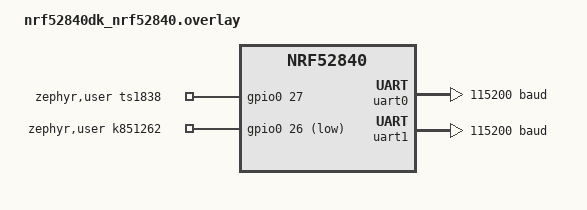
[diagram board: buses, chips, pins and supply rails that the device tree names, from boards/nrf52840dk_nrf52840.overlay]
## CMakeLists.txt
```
# SPDX-License-Identifier: Apache-2.0

cmake_minimum_required(VERSION 3.20.0)
find_package(Zephyr REQUIRED HINTS $ENV{ZEPHYR_BASE})
project(transmitter)

list(APPEND CMAKE_MODULE_PATH ${ZEPHYR_BASE}/modules/nanopb)
include(nanopb)
zephyr_nanopb_sources(app src/pc.proto)
FILE(GLOB app_sources src/*.c)

target_sources(app PRIVATE ${app_sources})

# ORIGINAL Targets (No NanoPB)
# target_sources(app PRIVATE src/main.c)
# zephyr_sources(src/shell_commands.c)
# zephyr_sources(src/hci.c)
# zephyr_sources(src/led_module.c)
# zephyr_sources(src/uart_module.c)
# zephyr_sources(src/ahu.c)
# zephyr_sources(src/ble_module.c)
# zephyr_sources(src/gcu_shell_cmds.c)
# zephyr_sources(src/ab_util.c)
```

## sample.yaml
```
sample:
  name: AHU
common:
  modules:
    - nanopb
tests:
  sample.basic.blinky:
    tags:
      - LED
      - gpio
    filter: dt_enabled_alias_with_parent_compat("led0", "gpio-leds")
    depends_on: gpio
    harness: led
    integration_platforms:
      - frdm_k64f
```

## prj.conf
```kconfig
# Configure GPIO (for LEDS)
CONFIG_GPIO=y

# Configure Logging & Shell
CONFIG_PRINTK=y
CONFIG_SHELL=y
CONFIG_SHELL_LOG_BACKEND=y
CONFIG_LOG=y
CONFIG_LOG_CMDS=y
CONFIG_LOG_RUNTIME_FILTERING=y
CONFIG_LOG_SPEED=y
CONFIG_LOG_DEFAULT_LEVEL=3
CONFIG_LOG_PRINTK=y
CONFIG_STATS=y
CONFIG_STATS_SHELL=y
CONFIG_CBPRINTF_FP_SUPPORT=y

# Uart
CONFIG_SERIAL=y
CONFIG_UART_INTERRUPT_DRIVEN=y

# RTT
CONFIG_USE_SEGGER_RTT=y
CONFIG_UART_CONSOLE=n
CONFIG_RTT_CONSOLE=y
CONFIG_SHELL_BACKEND_RTT=y
CONFIG_LOG_BACKEND_RTT_BUFFER=1
CONFIG_SHELL_BACKEND_RTT_BUFFER=0

# Bluetooth
CONFIG_BT=y
CONFIG_BT_OBSERVER=y
CONFIG_BT_SHELL=y
CONFIG_BT_FILTER_ACCEPT_LIST=y

# CONFIG
# CONFIG_INIT_STACKS=y
# CONFIG_THREAD_STACK_INFO=y
# CONFIG_KERNEL_SHELL=y
# CONFIG_THREAD_MONITOR=y
# CONFIG_BOOT_BANNER=n
# CONFIG_THREAD_NAME=y
# CONFIG_DEVICE_SHELL=y
# CONFIG_POSIX_CLOCK=y
# CONFIG_DATE_SHELL=y
# CONFIG_THREAD_RUNTIME_STATS=y
# CONFIG_THREAD_RUNTIME_STATS_USE_TIMING_FUNCTIONS=y
CONFIG_HEAP_MEM_POOL_SIZE=8192
CONFIG_NANOPB=y
# CONFIG_BT_CTLR_RX_PRIO_STACK_SIZE=2048
# CONFIG_MAIN_STACK_SIZE=16384
```

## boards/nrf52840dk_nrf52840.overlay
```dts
/*
 * Copyright (c) 2021 Jonathan Hahn
 *
 * SPDX-License-Identifier: Apache-2.0
 */

 / 
{
	zephyr,user {
		ts1838-gpios = <&gpio0 27 GPIO_ACTIVE_HIGH>;
		k851262-gpios = <&gpio0 26 GPIO_ACTIVE_LOW>;
	};
    
	aliases {
      uart-test = &uart1;
	  pc-software = &uart0;
	  ir-rx = &gpio0;
	  ir-tx = &gpio0;
	  ir-gpio = &gpio0;
   };
};

&uart0 {
	compatible = "nordic,nrf-uarte";
	status = "okay";
	current-speed = <115200>;
	pinctrl-0 = <&uart0_default>;
	pinctrl-1 = <&uart0_sleep>;
	pinctrl-names = "default", "sleep";
};

&uart1 {
	status = "okay";
	current-speed = <115200>;
	pinctrl-0 = <&uart1_default>;
	pinctrl-1 = <&uart1_sleep>;
	pinctrl-names = "default", "sleep";
};

&gpio0 {
	status = "okay";
	gpio-reserved-ranges = <0 2>, <6 1>, <8 3>, <17 7>;
	gpio-line-names = "XL1", "XL2", "AREF", "A0", "A1", "RTS", "TXD",
		"CTS", "RXD", "NFC1", "NFC2", "BUTTON1", "BUTTON2", "LED1",
		"LED2", "LED3", "LED4", "QSPI CS", "RESET", "QSPI CLK",
		"QSPI DIO0", "QSPI DIO1", "QSPI DIO2", "QSPI DIO3","BUTTON3",
		"BUTTON4", "SDA", "SCL", "A2", "A3", "A4", "A5";
};
```

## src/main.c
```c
 /** 
 **************************************************************
 * @file src/main.c
 * @author Alexander Burovanov - 46990480
 * @date 01052023
 * @brief Application Host Unit (AHU) Entry Point
 * REFERENCE: csse4011_prac1_ahu.pdf 
 ***************************************************************
 */

#include <stdio.h>
#include <zephyr/kernel.h>
#include <zephyr/sys_clock.h>
#include <zephyr/device.h>
#include <zephyr/sys/sys_heap.h>
#include "ahu.h"
#include "led_module.h"
#include "uart_module.h"
#include "ble_module.h"
#include "pc_module.h"
#include "ir_module.h"

// Define Priorities
#define UART_PRIORITY 2
#define AHU_PRIORITY 3
#define BLE_PRIORITY 3
#define PC_PRIORITY 3
#define IR_TX_PRIORITY 1

// Define Stack Sizes
#define UART_STACK_SIZE 1024
#define AHU_STACK_SIZE 2048
#define BLE_STACK_SIZE 4096
#define PC_STACK_SIZE 8192
#define IR_TX_STACK_SIZE 2048

// Create threads
K_THREAD_DEFINE(ahu_id, AHU_STACK_SIZE, ahu_handler, NULL, NULL, NULL,
		AHU_PRIORITY, 0, 0);
K_THREAD_DEFINE(uart_id, UART_STACK_SIZE, uart_handler, NULL, NULL, NULL,
		UART_PRIORITY, 0, 0);
K_THREAD_DEFINE(ble_id, BLE_STACK_SIZE, ble_handler, NULL, NULL, NULL,
		BLE_PRIORITY, 0, 0);
K_THREAD_DEFINE(pc_transmit_id, PC_STACK_SIZE, pc_comms_transmit_handler, NULL, NULL, NULL,
		PC_PRIORITY, 0, 0);
K_THREAD_DEFINE(pc_receive_id, PC_STACK_SIZE, pc_comms_receive_handler, NULL, NULL, NULL,
		PC_PRIORITY, 0, 0);		
K_THREAD_DEFINE(ir_tx_id, IR_TX_STACK_SIZE, ir_transmission_handler, NULL, NULL, NULL,
		IR_TX_PRIORITY, 0, 0);

/**
 * Application entry point
 * 
 * Returns: 0 upon exit
*/
int main(void) {

	// Initialise Hardware
	init_leds();
	init_ble();
	init_ir_module();

	return 0;
}
```

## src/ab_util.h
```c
 /** 
 **************************************************************
 * @file src/ab_util.h
 * @author Alexander Burovanov - 46990480
 * @date 25/03/2024
 * @brief AB's Utility Library
 * REFERENCE: None
 ***************************************************************
 */
#ifndef AB_UTIL_H_
#define AB_UTIL_H_
#include <zephyr/shell/shell.h>
#include <version.h>
#include <zephyr/logging/log.h>
#include <stdio.h>
#include <stdlib.h>
#include <zephyr/bluetooth/addr.h>
#include "uart_module.h"
#include "hci.h"
#include "led_module.h"
// #include "ble_module.h"

/**
 * Validates a floating point argument
 * 
 * value: the value to validate
 * returnLoc: a pointer to the return location
 * 
 * Returns: 0 on success, otherwise 1.
*/
extern int validate_float_arg(char* value, float* returnLoc);

/**
 * Validates an integer argument
 * 
 * value: the value to validate
 * returnLoc: a pointer to the return location
 * 
 * Returns: 0 on success, otherwise 1.
*/
extern int validate_int_arg(char* value, int* returnLoc);

/**
 * Validates a provided binary command line argument
 * 
 * value: the character to validate
 * 
 * Returns: 0 if value is 0, 1 if value is 1, 2 on error.
*/
extern int validate_binary_arg(char value);

/**
 * Gets a binary mask from a mask string
 * 
 * mask: a ptr to store the resulting mask
 * value: a string mask. E.g. "0010"
 * length: the length of the target mask E.g. 4
 * 
 * Returns: 0 on success, otherwise 1.
*/
extern uint8_t get_binary_mask(uint8_t* mask, char *value, uint8_t length);

/**
 * Validates a device id argument.
 * 
 * did: device id to verify
 * 
 * Result: 0 if valid, 1 otherwise.
*/
extern int validate_device_id(uint8_t did);

/**
 * Validates a provided filename arguments
 * 
 * fileName: filename being validated
 * 
 * Returns: 0 if valid. 1 if the filename is too long. 2 if the filename is invalid. 3 if the extension is invalid.
 * 
*/
extern int validate_file_name(char* fileName);

/**
 * Validates an BLE Address argument
 * 
 * value: the value to validate
 * returnLoc: a pointer to the return location
 * 
 * Returns: 0 on success, otherwise 1.
*/
extern int validate_ble_addr(char* value, bt_addr_le_t* returnLoc);

#endif
```

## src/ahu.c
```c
 /** 
 **************************************************************
 * @file src/ahu.c
 * @author Alexander Burovanov - 46990480
 * @date 01052023
 * @brief Application Host Unit Module
 * REFERENCE: csse4011_prac1_ahu.pdf 
 ***************************************************************
 */
#include <zephyr/kernel.h>
#include <zephyr/shell/shell.h>
#include <zephyr/logging/log.h>
#include <zephyr/logging/log_ctrl.h>
#include <zephyr/drivers/uart.h>

#include "ahu.h"
#include "hci.h"
#include "uart_module.h"
#include "pc_module.h"
#include "src/pc.pb.h"

// Register Logger
LOG_MODULE_REGISTER(ahu);

/* 1000 msec = 1 sec */
#define SLEEP_TIME_MS   1000

/**
 * Initialises the runtime logging levels for the project
 * 
 * Returns: 0 on exit
*/
static int initalise_log_levels(const struct device *dev) {
    ARG_UNUSED(dev);

	LogModule log_modules[] = {
		{"hci", LOG_LEVEL_INF},
        {"led_module", LOG_LEVEL_INF}
	};

	for (uint8_t i = 0; i < ARRAY_SIZE(log_modules); i++) {
		int sourceId = log_source_id_get(log_modules[i].module);
        if (sourceId < 0) {
            printk("Error: Log module %s not found\n", log_modules[i].module);
            continue;
        }
		log_filter_set(NULL, 0, sourceId, log_modules[i].level);
	}
    return 0;
}

SYS_INIT(initalise_log_levels, APPLICATION, CONFIG_APPLICATION_INIT_PRIORITY);

/**
 * AHU handler - handles the shell and interacts with the UART
 * 
 * Returns: 0 upon exit
*/
int ahu_handler(void) {
    const struct device *dev;
	uint32_t dtr = 0;

	dev = DEVICE_DT_GET(DT_CHOSEN(zephyr_shell_uart));
	if (!device_is_ready(dev)) {
		return 0;
	}

	while (!dtr) {
		#ifdef UART_SHELL
		uart_line_ctrl_get(dev, UART_LINE_CTRL_DTR, &dtr);
		k_sleep(K_MSEC(100));
		#endif

		#ifndef UART_SHELL
		// Run AHU in IR mode
		LOG_INF("Powered On");
		return 0;
		#endif
	}

    return 0;
}
```

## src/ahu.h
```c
 /** 
 **************************************************************
 * @file src/ahu.h
 * @author Alexander Burovanov - 46990480
 * @date 01052023
 * @brief Application Host Unit Module
 * REFERENCE: csse4011_prac1_ahu.pdf 
 ***************************************************************
 */
#ifndef AHU_H_
#define AHU_H_

// Groups a log module with an associated severity
typedef struct {
    const char* module;
    uint32_t level;
} LogModule;

// UART SHELL CONTROL
// Activate UART shell logic, otherwise default to using UART for GUI connection
// #define UART_SHELL

// THINGY52 BT CONTROL
// The AHU has the capability to automatically connect to a THINGY:52 and stream data from it's sensors to a PC.
// Uncomment the line below to activate this functionality
// #define THINGY52_BT

/**
 * AHU handler which handles the shell
 * 
 * Returns: 0 upon exit
*/
extern int ahu_handler(void);

#endif
```

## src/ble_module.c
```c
 /** 
 **************************************************************
 * @file src/ble_module.c
 * @author Alexander Burovanov - 46990480
 * @date 01052023
 * @brief Bluetooth Module
 * REFERENCE: csse4011_prac2_ahu.pdf 
 ***************************************************************
 */
#include <stdio.h>
#include <zephyr/kernel.h>
#include <zephyr/logging/log.h>
#include <zephyr/bluetooth/bluetooth.h>
#include <zephyr/bluetooth/hci.h>
#include <zephyr/sys/byteorder.h>
#include "hci.h"
#include "ble_module.h"
#include "pc_module.h"
#include "src/pc.pb.h"

// Setup logging
LOG_MODULE_REGISTER(ble_module, 4);

// Blecon semaphore
K_SEM_DEFINE(blecon_sem, 0, 1);
struct k_sem* blecon_sem_extern = &blecon_sem;

// Create the uart message queue
K_MSGQ_DEFINE(ble_receive, sizeof(BLECmd), 10, 4);

// Used to extern the uart msgq for use in other threads
struct k_msgq* ble_receive_extern = &ble_receive;

#define NAME_LEN 30
#define BLE_SCANNING() bleconActive || blescanActive

// BLE States
static uint8_t blescanActive = 0;
static uint8_t bleconActive = 0;
static uint8_t scanFilteringActive = 0;
bt_addr_le_t BLESCAN_FILTER_ADDR;
bt_addr_le_t BLECON_FILTER_ADDR;

/**
 * Returns the current BLE Scanning State of the Application
 * 
 * Returns: 0 if not scanning. 1 if blecon. 2 if blescan. 3 if both.
*/
int get_scanning_state() {
	if (blescanActive && bleconActive) {
		return 3;
	} else if (blescanActive) {
		return 2; 
	} else if (bleconActive) {
		return 1;
	} else {
		return 0;
	}
}

/**
 * Returns the mac address of a beacon based on id 
 * 
 * id: beacon id
 * mem: the memory location to store the returned string
 * 
 * Returns: the mac address string
*/
char* beacon_mac_from_id(uint8_t id, char* mem) {
	// Compare the received address to the available iBeacon node addresses.
	if (id == 1) {
		strcpy(mem, CSSE_4011_A_STR);
		return CSSE_4011_A_STR;
	} else if (id == 2) {
		strcpy(mem, CSSE_4011_B_STR);
		return CSSE_4011_B_STR;
	} else if (id == 3) {
		strcpy(mem, CSSE_4011_C_STR);
		return CSSE_4011_C_STR;
	} else if (id == 4) {
		strcpy(mem, CSSE_4011_D_STR);
		return CSSE_4011_D_STR;
	} else if (id == 5) {
		strcpy(mem, CSSE_4011_E_STR);
		return CSSE_4011_E_STR;
	} else if (id == 6) {
		strcpy(mem, CSSE_4011_F_STR);
		return CSSE_4011_F_STR;
	} else if (id == 7) {
		strcpy(mem, CSSE_4011_G_STR);
		return CSSE_4011_G_STR;
	} else if (id == 8) {
		strcpy(mem, CSSE_4011_H_STR);
		return CSSE_4011_H_STR;
	} else if (id == 9) {
		strcpy(mem, CSSE_4011_I_STR);
		return CSSE_4011_I_STR;
	} else if (id == 10) {
		strcpy(mem, CSSE_4011_J_STR);
		return CSSE_4011_J_STR;
	} else if (id == 11) {
		strcpy(mem, CSSE_4011_K_STR);
		return CSSE_4011_K_STR;
	} else if (id == 12) {
		strcpy(mem, CSSE_4011_L_STR);
		return CSSE_4011_L_STR;
	}
	return "00:00:00:00:00:00";
}

/**
 * Callback function which executes everytime a BT device is found
 * 
 * addr: bt address
 * rssi: bt rssi
 * type: packet type
 * ad: advertising data
 * 
 * Returns: void
*/
static void device_found(const bt_addr_le_t *addr, int8_t rssi, uint8_t type,
			 struct net_buf_simple *ad)
{
	char addr_str[BT_ADDR_LE_STR_LEN];
	int ret;
	bt_addr_le_to_str(addr, addr_str, sizeof(addr_str));

	if (blescanActive) {
		// Show all found devices
		if (scanFilteringActive) {
			// ret = bt_addr_le_cmp(&BLECON_FILTER_ADDR, addr);
			ret = bt_addr_cmp(&BLESCAN_FILTER_ADDR.a, &addr->a);
			if (ret == 0) {
				printk("blescan (f): %s (RSSI %d), type %u, AD data len %u\n", addr_str, rssi, type, ad->len);
			}
		} else {
			printk("blescan (all): %s (RSSI %d), type %u, AD data len %u\n", addr_str, rssi, type, ad->len);
		}
	}
	
	if(bleconActive) {
		// Record the data from the Thingy:52 Packets
		// ret = bt_addr_le_cmp(&BLECON_FILTER_ADDR, addr);
		ret = bt_addr_cmp(&BLECON_FILTER_ADDR.a, &addr->a);
		if (ret != 0) {
			// Not a Thingy:52 Packet
			return;
		}

		// Send the data via UART
		uint8_t did = ad->data[IBEACON_MAJOR_IDX - 1];
		uint8_t data3 = ad->data[IBEACON_MAJOR_IDX];
		uint8_t data2 = ad->data[IBEACON_MAJOR_IDX + 1];
		uint8_t data1 = ad->data[IBEACON_MINOR_IDX];
		uint8_t data0 = ad->data[IBEACON_MINOR_IDX + 1];
		uint32_t dataf;
		dataf = (data3 << 24) | (data2 << 16) | (data1 << 8) | data0;
		float dataF;;
		memcpy(&dataF, &dataf , sizeof(float));

		if (did == DID_RSSI || did == DID_TEMP || did == DID_HUM || did == DID_AP || did == DID_TVOC) {
			if (did == DID_RSSI) {
				// This is RSSI ranging information from the mobile node
				int dataBeacon = ad->data[IBEACON_MAJOR_IDX + 1];
				int8_t dataRssi = ad->data[IBEACON_MINOR_IDX + 1];
				LOG_DBG("DID: %d, BeaconID: %d, RSSI: %d\n", did, dataBeacon, dataRssi);
				
				// Filter the Packet (based on the filter list)
				sys_dnode_t* node;
				struct iBeaconNode template;
				int counter = 0;
				ret = 1;
				bt_addr_t temp1;
				bt_addr_t temp2;
				char addr1[20];
				for (node = sys_dlist_peek_head(&ibeaconNodes); node != NULL; node = sys_dlist_peek_next(&ibeaconNodes, node)) {
					// Get the container structure
					struct iBeaconNode* beaconNode = SYS_DLIST_CONTAINER(node, &template, node);
					addr = beacon_mac_from_id(dataBeacon, addr1);
					bt_addr_from_str(addr1, &temp1);
					bt_addr_from_str(beaconNode->data.bleMac, &temp2);

					// printk("ADDR1: %s\n", addr1);
					// printk("ADDR2: %s\n", beaconNode->data.bleMac);

					if (!bt_addr_cmp(&temp1, &temp2)) {
						ret = 0;
						break;
					}
					counter++;
				}

				// Send this information to the PC for processing
				if (!ret) {
					PCMessage* msgMalloc = k_malloc(PCMessage_size);
					msgMalloc->cmd = PCCommand_PC_CMD_RSSI;
					msgMalloc->beacon_id = dataBeacon;
					msgMalloc->rssi = dataRssi;
					k_msgq_put(pc_transmit_extern, (uint8_t*)msgMalloc, K_FOREVER);
					k_free(msgMalloc);
					// k_sleep(K_MSEC(100));
				}
			} else {
				// This is a sensor data packet
				LOG_DBG("DID: %d, Data: [%X %X %X %X], %f\n", did, data3, data2, data1, data0, (double)dataF);
				// LOG_DBG("blecon: %s (RSSI %d), type %u, AD data len %u\n", addr_str, rssi, type, ad->len);

				SensorData data = {did, (float)dataF};
				send_uart_packet(PACKET_PRE, PACKET_REQ, CMD_SENSOR, (uint8_t*)&data);
			}
		}
	}
}

/**
 * Start BLE Scanning
 *  
 * Returns: void
*/
int start_ble_scanning() {
	// Note: set .options to 0 for normal operation (without whitelist)
	struct bt_le_scan_param scan_param = {
		.type       = BT_LE_SCAN_TYPE_PASSIVE,
		.options    = BT_LE_SCAN_OPT_FILTER_ACCEPT_LIST,
		.interval   = BT_GAP_SCAN_FAST_INTERVAL,
		.window     = BT_GAP_SCAN_FAST_WINDOW,
	};

	int err;

	bt_addr_le_from_str(THINGY_STR, "random", &THINGY52_ADDR);

	err = bt_le_whitelist_add(&THINGY52_ADDR);
    if (err) {
        LOG_ERR("Failed to add address to the whitelist (err %d)\n", err);
        return err;
    }

    err = bt_le_scan_start(&scan_param, device_found);
	if (err) {
		LOG_ERR("Start scanning failed (err %d)\n", err);
		return err;
	}

	return 0;
}

/**
 * BLE message controller. Sends and receives UART message between the peripherals.
 * 
 * Returns: 0 upon exit
*/
int ble_handler(void) {
	
	// Init Delay
	k_sleep(K_MSEC(100));

	BLECmd bleCmd;
	char addr_str[BT_ADDR_STR_LEN];
	while (k_msgq_get(&ble_receive, &bleCmd, K_FOREVER) == 0) {
		// Process BLE Commands as they are received
		switch (bleCmd.bleCmd) {
			case BLECON_START:
				// Start Receiving Data from the Thingy:52
				if (!BLE_SCANNING()) {
					start_ble_scanning();
				}
				bleconActive = 1;
				if (!bt_addr_cmp(&bleCmd.addr.a, &BLECON_FILTER_ADDR.a)) {
					bt_addr_to_str(&BLECON_FILTER_ADDR.a, addr_str, sizeof(addr_str));
					LOG_WRN("Sensor data from BT Address [%s] is already being captured.\n", addr_str);
				}
				BLECON_FILTER_ADDR = bleCmd.addr;

				break;
			case BLECON_STOP:
				// Stop Receiving Data from the Thingy:52
				if (!BLE_SCANNING()) {
					LOG_WRN("Bluetooth scanning is not currently active.");
				}
				bleconActive = 0;
				if (!BLE_SCANNING()) {
					bt_le_scan_stop();
				}
				
				break;
			case BLESCAN_START:
				// Start BLE Scanning (without filtering)
				if (!BLE_SCANNING()) {
					start_ble_scanning();
				}
				blescanActive = 1;

				break;
			case BLESCAN_STARTF:
				if (!BLE_SCANNING()) {
					start_ble_scanning();
				}
				if (!bt_addr_cmp(&bleCmd.addr.a, &BLESCAN_FILTER_ADDR.a)) {
					bt_addr_to_str(&BLESCAN_FILTER_ADDR.a, addr_str, sizeof(addr_str));
					LOG_WRN("Packets from BT Address [%s] are already being filtered.\n", addr_str);
				}
				blescanActive = 1;
				scanFilteringActive = 1;
				BLESCAN_FILTER_ADDR = bleCmd.addr;

				break;
			case BLESCAN_STOP:
				// Stop BLE Scanning
				if (!BLE_SCANNING()) {
					LOG_WRN("Bluetooth scanning is not currently active.");
				}
				blescanActive = 0;
				scanFilteringActive = 0;
				if (!BLE_SCANNING()) {
					bt_le_scan_stop();
				}
				
				break;
		}
	}
	return 0;
}

/**
 * Initialises BLE Hardware
 * 
 * Returns: 0 on success
*/
int init_ble() {
    int err;

	LOG_DBG("Initialising BLE\n");

	/* Initialize the Bluetooth Subsystem */
	err = bt_enable(NULL);
	if (err) {
		printk("Bluetooth init failed (err %d)\n", err);
		return 0;
	}

	return 0;
}
```

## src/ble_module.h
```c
 /** 
 **************************************************************
 * @file src/ble_module.h
 * @author Alexander Burovanov - 46990480
 * @date 01052023
 * @brief Bluetooth Module
 * REFERENCE: csse4011_prac2_ahu.pdf 
 ***************************************************************
 */
#ifndef AB_BLE_MODULE_H_
#define AB_BLE_MODULE_H_
#include <zephyr/bluetooth/bluetooth.h>

// BLE MESSAGE QUEUE'S
extern struct k_sem* blecon_sem_extern;
extern struct k_msgq* ble_receive_extern;

// Fixed Addresses
const static char* THINGY_STR = "fe:95:bb:55:92:ef";
static bt_addr_le_t THINGY52_ADDR;

// BLE CMDS
#define BLECON_START 0x01
#define BLECON_STOP 0x02
#define BLESCAN_START 0x03
#define BLESCAN_STARTF 0x04
#define BLESCAN_STOP 0x05

// BLE CMD Type
typedef struct {
    uint8_t bleCmd;
    bt_addr_le_t addr;
} BLECmd;

/**
 * Initialises BLE Hardware
 * 
 * Returns: 0 on success
*/
extern int init_ble();

/**
 * UART message controller. Sends and receives UART message between the peripherals.
 * 
 * Returns: 0 upon exit
*/
extern int ble_handler();

/**
 * Returns the current BLE Scanning State of the Application
 * 
 * Returns: 0 if not scanning. 1 if blecon. 2 if blescan. 3 if both.
*/
extern int get_scanning_state();

#endif
```

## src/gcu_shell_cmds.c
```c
 /** 
 **************************************************************
 * @file src/gcu_shell_cmds.c
 * @author Alexander Burovanov - 46990480
 * @date 25/03/2024
 * @brief GCU Shell Commands
 * REFERENCE: None
 ***************************************************************
 */
#include <zephyr/shell/shell.h>
#include <version.h>
#include <zephyr/logging/log.h>
#include <stdio.h>
#include <stdlib.h>
#include <zephyr/bluetooth/addr.h>

#include "uart_module.h"
#include "hci.h"
#include "led_module.h"
#include "ble_module.h"
#include "ab_util.h"

// Setup logging
LOG_MODULE_DECLARE(ahu);

/**
 * Draws a point on the GCU
 * 
 * sh: shell
 * argc: number of args
 * argv: provided args
 * 
 * Returns: 0 on success, 1 on failure
*/
static int gcu_cmd_point(const struct shell *sh, size_t argc, char **argv)
{
	#ifdef DEBUG
	shell_print(sh, "Argc: %d. Arg: %s, %s, %s", argc, argv[0], argv[1], argv[2]);
	#endif
	if (argc != 3) {
		LOG_ERR("Point: Invalid Command");
		return 1;
	}

	// Validate cmd line args
	float x, y, ret = 0;
	ret = ret + validate_float_arg(argv[1], &x);
	ret = ret + validate_float_arg(argv[2], &y);
	if (ret > 0) {
		LOG_ERR("point: Invalid Command");
		return 1;
	}

	// Construct and send UART Packet
	send_uart_packet(PACKET_PRE, PACKET_REQ, CMD_POINT, (uint8_t*)&(PointData){(float)x, (float)y});

	return 0;
}

/**
 * Draws a cirlce on the GCU
 * 
 * sh: shell
 * argc: number of args
 * argv: provided args
 * 
 * Returns: 0 on success, 1 on failure
*/
static int gcu_cmd_circle(const struct shell *sh, size_t argc, char **argv) {
	if (argc != 4) {
		LOG_ERR("circle: Invalid Command");
		return 1;
	}

	// Validate cmd line args
	float r, x, y, ret = 0;
	ret = ret + validate_float_arg(argv[1], &r);
	ret = ret + validate_float_arg(argv[2], &x);
	ret = ret + validate_float_arg(argv[3], &y);
	if (ret > 0) {
		LOG_ERR("circle: Invalid Command - incorrect args provided!");
		return 1;
	} else if (r < 0) {
		LOG_ERR("circle: Invalid Command - radius cannot be negative!");
		return 1;
	}

	// Send Packet Via UART
	send_uart_packet(PACKET_PRE, PACKET_REQ, CMD_CIRCLE, (uint8_t*)&(CircleData){(float)r, (float)x, (float)y});

	return 0;
}

/**
 * Draws a cirlce on the GCU
 * 
 * sh: shell
 * argc: number of args
 * argv: provided args
 * 
 * Returns: 0 on success, 1 on failure
*/
static int gcu_cmd_lissajous(const struct shell *sh, size_t argc, char **argv) {
	// Validate cmd line args
	float a, b, t, ret = 0;
	ret = ret + validate_float_arg(argv[1], &a);
	ret = ret + validate_float_arg(argv[2], &b);
	ret = ret + validate_float_arg(argv[3], &t);
	if (ret > 0) {
		LOG_ERR("lj: Invalid Command - incorrect args provided!");
		return 1;
	}

	// Send Packet Via UART
	send_uart_packet(PACKET_PRE, PACKET_REQ, CMD_LJ, (uint8_t*)&(LissajousData){(float)a, (float)b, (float)t});

	return 0;
}

/**
 * Sets the X and Y voltages on the GCU Dac.
 * 
 * sh: shell
 * argc: number of args
 * argv: provided args
 * 
 * Returns: 0 on success, 1 on failure
*/
static int gcu_cmd_dac(const struct shell *sh, size_t argc, char **argv) {
	// Validate cmd line args
	float x, y, ret = 0;
	ret = ret + validate_float_arg(argv[1], &x);
	ret = ret + validate_float_arg(argv[2], &y);
	if (ret > 0) {
		LOG_ERR("dac: Invalid Command - incorrect args provided!");
		return 1;
	}

	// Send Packet Via UART
	send_uart_packet(PACKET_PRE, PACKET_REQ, CMD_DAC, (uint8_t*)&(DacData){(float)x, (float)y});

	return 0;
}

/**
 * Draws a cirlce on the GCU
 * 
 * sh: shell
 * argc: number of args
 * argv: provided args
 * 
 * Returns: 0 on success, 1 on failure
*/
static int gcu_cmd_gled(const struct shell *sh, size_t argc, char **argv) {
	// Convert Argv to byte
	int len = strlen(argv[1]) + strlen(argv[2]) + strlen(argv[3]);
	if (len > 3) {
		LOG_ERR("gled: Invalid Command - incorrect args provided!");
		return 1;
	}

	// Validate cmd line args
	uint8_t r = validate_binary_arg(argv[1][0]);
	uint8_t g = validate_binary_arg(argv[2][0]);
	uint8_t b = validate_binary_arg(argv[3][0]);

	if ((r + g + b) > 3) {
		LOG_ERR("gled: Invalid Command - incorrect args provided!");
		return 1;
	}

	// Send Packet Via UART
	send_uart_packet(PACKET_PRE, PACKET_REQ, CMD_GLED, (uint8_t*)&(RGBData){(uint8_t)r, (uint8_t)g, (uint8_t)b});

	return 0;
}

static int gcu_cmd_gpb(const struct shell *sh, size_t argc, char **argv) {
	// Send Packet Via UART
	send_uart_packet(PACKET_PRE, PACKET_REQ, CMD_GPB, NULL);

	return 0;
}

/**
 * Draws a graph of the specified sensor on the GCU.
 * 
 * sh: shell
 * argc: number of args
 * argv: provided args
 * 
 * Returns: 0 on success, 1 on failure
*/
static int gcu_cmd_gcugraph(const struct shell *sh, size_t argc, char **argv) {
	// Validate cmd line args
	int deviceId, ret = 0;
	ret = ret + validate_int_arg(argv[1], &deviceId);
	if (ret > 0) {
		LOG_ERR("gcugraph: Invalid Command - incorrect args provided!");
		return 1;
	}

	if (validate_device_id(deviceId)) {
		LOG_ERR("gcugraph: Invalid deviceId specified!");
		return 1;
	}

	if (get_scanning_state() == 0 || get_scanning_state() == 2) {
		// Not listening for Thing52 iBeacon
		LOG_WRN("gcugraph: Not connected to iBeacon!");
	}

	// Send Packet Via UART
	// print_contents(CMD_GRAPH, (uint8_t*)&(DeviceIdData){(uint8_t)deviceId});
	send_uart_packet(PACKET_PRE, PACKET_REQ, CMD_GRAPH, (uint8_t*)&(DeviceIdData){(uint8_t)deviceId});

	return 0;
}


/**
 * Draws a meter of the specified sensor on the GCU.
 * 
 * sh: shell
 * argc: number of args
 * argv: provided args
 * 
 * Returns: 0 on success, 1 on failure
*/
static int gcu_cmd_gcumeter(const struct shell *sh, size_t argc, char **argv) {
	// Validate cmd line args
	int deviceId, ret = 0;
	ret = ret + validate_int_arg(argv[1], &deviceId);
	if (ret > 0) {
		LOG_ERR("gcumeter: Invalid Command - incorrect args provided!");
		return 1;
	}

	if (validate_device_id(deviceId)) {
		LOG_ERR("gcumeter: Invalid deviceId specified!");
		return 1;
	}

	if (get_scanning_state() == 0 || get_scanning_state() == 2) {
		// Not listening for Thing52 iBeacon
		LOG_WRN("gcumeter: Not connected to iBeacon!");
	}

	// Send Packet Via UART
	send_uart_packet(PACKET_PRE, PACKET_REQ, CMD_METER, (uint8_t*)&(DeviceIdData){(uint8_t)deviceId});

	return 0;
}

/**
 * Draws a numeric (SSD) of the specified sensor on the GCU.
 * 
 * sh: shell
 * argc: number of args
 * argv: provided args
 * 
 * Returns: 0 on success, 1 on failure
*/
static int gcu_cmd_gcunumeric(const struct shell *sh, size_t argc, char **argv) {
	// Validate cmd line args
	int deviceId, ret = 0;
	ret = ret + validate_int_arg(argv[1], &deviceId);
	if (ret > 0) {
		LOG_ERR("gcunumeric: Invalid Command - incorrect args provided!");
		return 1;
	}

	if (validate_device_id(deviceId)) {
		LOG_ERR("gcunumeric: Invalid deviceId specified!");
		return 1;
	}

	if (get_scanning_state() == 0 || get_scanning_state() == 2) {
		// Not listening for Thing52 iBeacon
		LOG_WRN("gcunumeric: Not connected to iBeacon!");
	}

	// Send Packet Via UART
	send_uart_packet(PACKET_PRE, PACKET_REQ, CMD_NUMERIC, (uint8_t*)&(DeviceIdData){(uint8_t)deviceId});

	return 0;
}

/**
 * Starts recording data to the SD card.
 * 
 * sh: shell
 * argc: number of args
 * argv: provided args
 * 
 * Returns: 0 on success, 1 on failure
*/
static int gcu_cmd_gcurec_s(const struct shell *sh, size_t argc, char **argv) {
	// Validate cmd line args
	int deviceId, ret = 0;
	char fileName[FILE_NAME_MAX_LEN];
	ret = ret + validate_int_arg(argv[1], &deviceId);
	if (ret > 0) {
		LOG_ERR("gcurec: Invalid Command - incorrect args provided!");
		return 1;
	}

	// Validate fileName value
	ret = validate_file_name(argv[2]);
	if (ret == 1) {
		LOG_ERR("gcurec: Invalid filename - name too long!");
		return 1;
	} else if (ret == 2) {
		LOG_ERR("gcurec: Invalid filename!");
		return 1;	
	} else if (ret == 3) {
		LOG_ERR("gcurec: Invalid extension! Only .csv is accepted!");
		return 1;
	}
	memcpy(fileName, argv[2], strlen(argv[2]));

	// Validate device id value
	if (validate_device_id(deviceId)) {
		LOG_ERR("gcurec: Invalid deviceId specified!");
		return 1;
	}

	// Check scanning state
	if (get_scanning_state() == 0 || get_scanning_state() == 2) {
		// Not listening for Thing52 iBeacon
		LOG_WRN("gcurec: Not connected to iBeacon!");
	}

	// Send Packet Via UART
	strcpy((char*)fileNameG, argv[2]);
	send_uart_packet(PACKET_PRE, PACKET_REQ, CMD_REC, (uint8_t*)&(RecData){(uint8_t)GCU_REC_S, deviceId, fileName});
	return 0;
}

/**
 * Stops recording data to the SD card.
 * 
 * sh: shell
 * argc: number of args
 * argv: provided args
 * 
 * Returns: 0 on success, 1 on failure
*/
static int gcu_cmd_gcurec_p(const struct shell *sh, size_t argc, char **argv) {
	// Check scanning state
	if (get_scanning_state() == 0 || get_scanning_state() == 2) {
		// Not listening for Thing52 iBeacon
		LOG_WRN("gcurec: Not connected to iBeacon!");
	}

	// Stop BLE Data Receiving
	send_uart_packet(PACKET_PRE, PACKET_REQ, CMD_REC, (uint8_t*)&(RecData){(uint8_t)GCU_REC_P});

	return 0;
}

// Define GCU Shell Commands
SHELL_CMD_ARG_REGISTER(point, NULL, "Draws a point on the Graphical Plotter Display.\nUSAGE: point <x> <y>\n<x> - x position, <y> - y position", gcu_cmd_point, 3, 0);
SHELL_CMD_ARG_REGISTER(circle, NULL, "Draws a circle on the Graphical Plotter Display.\nUSAGE: circle <r> <x> <y>\n<r> - radius, <x> - x position, <y> - y position", gcu_cmd_circle, 4, 0);
SHELL_CMD_ARG_REGISTER(lj, NULL, "Draws a lissajous curve on the Graphical Plotter Display.\nUSAGE: circle <a> <b> <t>\n<a> - amplitude 1, <b> - amplitude 2, <t> - phase shift (deg)", gcu_cmd_lissajous, 4, 0);
SHELL_CMD_ARG_REGISTER(dac, NULL, "Sets the X and Y DAC voltages on the Graphical Plotter Display.\nUSAGE: dac <x> <y>\n<x> - x voltage, <y> - y voltage", gcu_cmd_dac, 3, 0);
SHELL_CMD_ARG_REGISTER(gled, NULL, "Toggles the onboard device LEDs on the Graphical Plotter Display.\nUSAGE: gled <r> <g> <b>\n<r> - red led, <g> - green led, <b> - blue led", gcu_cmd_gled, 4, 0);
SHELL_CMD_ARG_REGISTER(gpb, NULL, "Read the pushbutton state from the GCU.", gcu_cmd_gpb, 1, 0);
SHELL_CMD_ARG_REGISTER(gcugraph, NULL, "Draws a graph with the specified sensor data on the Graphical Plotter Display.\nUSAGE: gcugraph <device id>\n<device id> - specified sensor", gcu_cmd_gcugraph, 2, 0);
SHELL_CMD_ARG_REGISTER(gcumeter, NULL, "Draws a meter with the specified sensor data on the Graphical Plotter Display.\nUSAGE: gcumeter <device id>\n<device id> - specified sensor", gcu_cmd_gcumeter, 2, 0);
SHELL_CMD_ARG_REGISTER(gcunumeric, NULL, "Draws a SSD numeric with the specified sensor data on the Graphical Plotter Display.\nUSAGE: gcunumeric <device id>\n<device id> - specified sensor", gcu_cmd_gcunumeric, 2, 0);
SHELL_STATIC_SUBCMD_SET_CREATE(sub_gcurec,
	SHELL_CMD_ARG(-s, NULL, "Starts recording the Plot values to the SD card.\nUSAGE: gcurec -s <device id> <file name>", gcu_cmd_gcurec_s, 3, 0),
	SHELL_CMD_ARG(-p, NULL, "Stops recording the Plot values to the SD card..\nUSAGE: gcurec -p", gcu_cmd_gcurec_p, 1, 0),
	SHELL_SUBCMD_SET_END
);
SHELL_CMD_ARG_REGISTER(gcurec, &sub_gcurec, "Records the Graphical Plotter Display values to the onboard SD Card.\n", NULL, 1, 1);
```

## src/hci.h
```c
 /** 
 **************************************************************
 * @file src/hci.h
 * @author Alexander Burovanov - 46990480
 * @date 01052023
 * @brief Host Controller Communication Protocol
 * REFERENCE: csse4011_prac1_hci.pdf 
 ***************************************************************
 */
#ifndef COMMS_H_
#define COMMS_H_

#include <stdint.h>
#include <zephyr/drivers/uart.h>
#define UART_MODULE_ENABLED

// Packet Type
#define PACKET_REQ 0x01
#define PACKET_RES 0x02
#define PACKET_PRE 0xAA

// Command Types
#define CMD_POINT 0x01
#define CMD_CIRCLE 0x02
#define CMD_LJ 0x03
#define CMD_DAC 0x04
#define CMD_GLED 0x05
#define CMD_GPB 0x06
#define CMD_GRAPH 0x07 // Draw graph plot on GCU
#define CMD_METER 0x08 // Draw meter on GCU
#define CMD_NUMERIC 0x09 // Draw SSD value on GCU
#define CMD_REC 0x10 // Start/Stop Recording
#define CMD_SENSOR 0x11 // Sensor Data

// Device IDs
#define DID_LEDS 1
#define DID_PB 2
#define DID_DAC 3
#define DID_LJP 4
#define DID_TEMP 5 // Temperature Sensor
#define DID_HUM 6 // Humidity Sensor
#define DID_AP 7 // Air Pressure Sensor
#define DID_TVOC 8 // Organic Compound Sensor
#define DID_SD 13 // SD Card Writer
#define DID_RSSI 9 // RSSI Mobile Node

// IR Protocols
#define IR_PROTO_NEC 0

/**
 * A struct which store IR data packets
*/
typedef struct {
    uint8_t protocol;
    uint32_t data;
} IRData;


// Response Types
#define RES_OK 0x01
#define RES_FAIL 0x02

// PB States
#define PB_ON 0x01
#define PB_OFF 0x02

// File Name Length
#define FILE_NAME_MAX_LEN 10 // Including '\n' character
#define GCU_REC_S 0x01 // Start SD Card Recording
#define GCU_REC_P 0x02 // Stop SD Card Recording
extern char fileNameG[FILE_NAME_MAX_LEN]; // File Name Placeholder

// BLE MACROS
#define IBEACON_MAJOR_IDX 25
#define IBEACON_MINOR_IDX 27

// THINGY52 Modes
#define SENSOR_MODE 1
#define RANGING_MODE 2
const static uint8_t mode = RANGING_MODE;

// Packet & Associated Data Types
/**
 * A HCI data packet.
*/
typedef struct __attribute__((__packed__)) {
    uint8_t preamble;
    uint8_t typeAndLength;
    uint8_t command;
    uint8_t* data; // Note flatten this out of the struct before sending via uart
} Packet;

/**
 * A  HCI data packet which does not point to data contents - suitable for uart transmission.
*/
typedef struct __attribute__((__packed__)) {
    uint8_t preamble;
    uint8_t typeAndLength;
    uint8_t command;
} StrippedPacket;

/**
 * A XY data packet
*/
typedef struct __attribute__((__packed__)) {
    float x;
    float y;
} XYData;

/**
 * A Point data packet
*/
typedef XYData PointData;

/**
 * A DAC data packet
*/
typedef XYData DacData;

/**
 * A Circle data packet
*/
typedef struct __attribute__((__packed__)) {
    float r;
    float x;
    float y;
} CircleData;

/**
 * A Lissajous data packet
*/
typedef struct __attribute__((__packed__)) {
    float a;
    float b;
    float t;
} LissajousData;

/**
 * A RGB data packet
*/
typedef struct __attribute__((__packed__)) {
    uint8_t r;
    uint8_t g;
    uint8_t b;
} RGBData;

/**
 * A DeviceId data packet
*/
typedef struct __attribute__((__packed__)) {
    uint8_t deviceId;
} DeviceIdData;

/**
 * A Sensor data packet
*/
typedef struct __attribute__((__packed__)) {
    uint8_t deviceId;
    float data;
} SensorData;

/**
 * A RSSI data packet
*/
typedef struct __attribute__((__packed__)) {
    uint8_t deviceId;
    uint8_t beacon;
    int8_t rssi;
} RSSIData;

/**
 * SD Recording data packet
*/
typedef struct __attribute__((__packed__)) {
    uint8_t cmd;
    uint8_t deviceId;
    uint8_t fileName[FILE_NAME_MAX_LEN];
} RecData;

/**
 * A generic response packet
*/
typedef struct __attribute__((__packed__)) {
    uint8_t resCode;
} GeneralResponse;

/**
 * A push button state response packet
*/
typedef struct __attribute__((__packed__)) {
    GeneralResponse status;
    uint8_t state;
} PBResponse;

// Function Definitions
/**
 * Combines the type and data length arguments into a single byte.
 * 
 * type: the packet type
 * length: the length of the packet data
 * 
 * Returns: the combined byte
*/
extern uint8_t combine_type_and_length(uint8_t type, uint8_t length);

/**
 * Determines the size of the data contents based on the command.
 * 
 * cmd: the provided command
 * 
 * Returns: the size of the data contents associated to the command. 0 if no command found.
*/
extern uint8_t determine_contents_size(uint8_t cmd);

/**
 * Prints the data contents of each command
 * 
 * cmd: the command associated to the data
 * data: the data to print
 * 
 * Returns: void
*/
extern void print_contents(uint8_t cmd, uint8_t* data);

#ifdef UART_MODULE_ENABLED
/**
 * Sends a packet via UART
 * 
 * uartdev: UART device node
 * preamble: packet preamble
 * packetType: the packet type (request/response)
 * command: the command executed
 * data: the content for the relevant command.
 * NOTE: it is the caller's responsibity to ensure the content data type matches the command provided.
 * 
 * Returns: void * 
*/
extern void send_uart_packet(uint8_t preamble, uint8_t packetType, uint8_t command, uint8_t* data);

/**
 * Receives and processes a packet from UART.
 * 
 * buffer: the buffer of received bytes
 * 
 * Returns: a ptr to a packet
 * NOTE: this function will allocate memory for the data contents. It is the responsibility
 *       of the caller to free this memory after use by calling `k_free()`.
*/
extern Packet receive_uart_packet(uint8_t* buffer);
#endif

#endif
```

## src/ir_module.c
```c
 /** 
 **************************************************************
 * @file src/ir_module.c
 * @author Alexander Burovanov - 46990480
 * @date 04/05/2024
 * @brief IR RX/TX Driver
 * REFERENCE: none
 ***************************************************************
 */
#include "ir_module.h"
#include <stdio.h>
#include <zephyr/drivers/gpio.h>
#include <zephyr/logging/log.h>
#include "hci.h"
#include "src/pc.pb.h"
#include "pc_module.h"

// Init Logging Module
LOG_MODULE_REGISTER(ir_module, 3);

// Define the GPIO pins connected to RX/TX
#define ZEPHYR_USER_NODE DT_PATH(zephyr_user)
#define IR_RX_GPIO_PIN 27
#define IR_TX_GPIO_PIN 26
#define TS1838_SIGNAL_STABILIZATION_TIME_MS 50
static const struct gpio_dt_spec ir_rx_pin = GPIO_DT_SPEC_GET(ZEPHYR_USER_NODE, ts1838_gpios);
static const struct gpio_dt_spec ir_tx_pin = GPIO_DT_SPEC_GET(ZEPHYR_USER_NODE, k851262_gpios);

// Define IR RX signal state and data structures
static uint32_t ir_data = 0;
static uint16_t pulseCount = 0;
static uint8_t rxTimerMs = 0;
static float txTimerUs = 0;

#define RX_TIMER_TIMEOUT 150 // The timer is automatically stopped if it ticks for more than 150ms
#define TX_TIMER_TIMEOUT 68 * 1000 * 1000 // (68ms => ns)
// IR Transmit transmission message queue
K_MSGQ_DEFINE(ir_transmit_q, sizeof(IRData), 10, 1);

// Used to extern the uart msgq for use in other threads
struct k_msgq* ir_transmit_q_extern = &ir_transmit_q;

// Function Prototypes
void increment_rx_timer(struct k_work *work);
void increment_tx_timer(struct k_work *work);

// System worker thread to execute timer operations
K_WORK_DEFINE(rx_timer_work, increment_rx_timer);
K_WORK_DEFINE(tx_timer_work, increment_tx_timer);

/**
 * Timer handler which triggers when the timer expires
 * Calls increment_rx_timer to perform the counting operation
 * 
 * Returns: void
 * 
*/
static void ir_rx_timer_step_handler(struct k_timer *timer_id) {
    k_work_submit(&rx_timer_work);
}

/**
 * Resets the timer when it is stopped
 * 
 * Returns: void
 * 
*/
static void ir_rx_timer_stop_handler(struct k_timer *timer_id) {
    // If the timer times out then reset the pulse count
    pulseCount = 0;
    rxTimerMs = 0;
    LOG_INF("Timer Stopped");
}

/**
 * Timer handler which triggers when the timer expires
 * Calls increment_rx_timer to perform the counting operation
 * 
 * Returns: void
 * 
*/
static void ir_tx_timer_step_handler(struct k_timer *timer_id) {
    k_work_submit(&tx_timer_work);
}

/**
 * Resets the timer when it is stopped
 * 
 * Returns: void
*/
static void ir_tx_timer_stop_handler(struct k_timer *timer_id) {
    txTimerUs = 0;
    LOG_INF("Tx Timer Stopped");
}

// IR timeout timer to track the time differences between IR pulses
K_TIMER_DEFINE(ir_rx_timeout_timer, ir_rx_timer_step_handler, ir_rx_timer_stop_handler);
K_TIMER_DEFINE(ir_tx_timeout_timer, ir_tx_timer_step_handler, ir_tx_timer_stop_handler);

/**
 * Increments the ir_rx_timeout_timer
 * 
 * Returns: void
*/
void increment_rx_timer(struct k_work *work)
{
    if (rxTimerMs >= RX_TIMER_TIMEOUT) {
        LOG_INF("Timer Timed Out");
        k_timer_stop(&ir_rx_timeout_timer);
    }
    rxTimerMs++;
}

/**
 * Increments the ir_tx_timeout_timer
 * 
 * Returns: void
*/
void increment_tx_timer(struct k_work *work)
{
    // if (timerMs >= TX_TIMER_TIMEOUT) {
    //     LOG_INF("Timer Timed Out");
    //     k_timer_stop(&ir_rx_timeout_timer);
    // }
    txTimerUs += 0.5;
}

/**
 * Checks to see if the provided pulse is a data bit
 * 
 * Returns: True if the pulse is a data pulse, False otherwise
 * 
*/
static bool is_bit_pulse(uint16_t pulse) {
    return 3 <= pulse && pulse <= 34;
}

/**
 * Checks to see if the provided pulse is the end of a message
 * 
 * Returns: True if the message is complete, False otherwise
 * 
*/
static bool is_message_pulse(uint16_t pulse) {
    return pulse == 34;
}

/**
 * GPIO Callback function - executes on falling GPIO falling edge triggers
 * 
 * Returns: void
 * 
*/
static void ir_signal_callback(const struct device *dev, struct gpio_callback *cb, uint32_t pins) {
    // Check if the GPIO pin triggered the callback
    if (pins & BIT(IR_RX_GPIO_PIN)) {
        // Read IR Receiver Pin
        int pin_value = gpio_pin_get(dev, IR_RX_GPIO_PIN);
        if (pin_value < 0) {
            LOG_ERR("Error reading GPIO pin: %d", pin_value);
            return;
        }
        pulseCount++;

        // Check if the current falling edge is a bit pulse
        if (is_bit_pulse(pulseCount)) {
            // Decode Bit Value
            ir_data <<= 1;
            printk("Pulse Count: %d, Timer: %d\n", pulseCount, rxTimerMs);
            ir_data += (rxTimerMs >= 2) ? 1 : 0;
        }

        // Measure
        if (is_message_pulse(pulseCount)) {
            // TODO: save to a queue/send to PC
            k_timer_stop(&ir_rx_timeout_timer);
            LOG_INF("IR Data 0x%x", ir_data);

            // Send the data to the PC
            PCMessage* msgMalloc = k_malloc(PCMessage_size);
            msgMalloc->cmd = PCCommand_PC_CMD_IRCODE;
            msgMalloc->irCode = ir_data;
            k_msgq_put(pc_transmit_extern, (uint8_t*)msgMalloc, K_FOREVER);
            k_free(msgMalloc);
        }

        rxTimerMs = 0;
        k_timer_start(&ir_rx_timeout_timer, K_MSEC(1), K_MSEC(1));
    }
}

/**
 * Initialises the IR Rx & Tx
 * 
 * Returns: 0 on success
 * 
*/
int init_ir_module() {

    uint8_t ret = 0;

    // Configure Receiver
    // Configure RX GPIO pin
	if (!gpio_is_ready_dt(&ir_rx_pin)) {
        LOG_ERR("Failed to initialise TS1838!");
        return 1;
	}
    ret = ret + gpio_pin_configure_dt(&ir_rx_pin, GPIO_INPUT);
    if (ret > 0) {
        LOG_ERR("Failed to initalise LEDS!");
        return 1;
    }

    // Get the GPIO device
    const struct device *gpio_dev = ir_dev;
    if (!gpio_dev) {
        printk("Could not get GPIO device\n");
        return -ENODEV;
    }
    struct gpio_callback gpio_cb;

    // Set up a callback for IR signal detection
    gpio_init_callback(&gpio_cb, ir_signal_callback, BIT(IR_RX_GPIO_PIN));
    ret = gpio_add_callback(gpio_dev, &gpio_cb);
    if (ret < 0) {
        LOG_ERR("Failed to set up callback: %d", ret);
        return ret;
    }

    // Enable interrupt on rising edge (or falling edge, depending on IR sensor)
    ret = gpio_pin_interrupt_configure_dt(&ir_rx_pin, GPIO_INT_EDGE_FALLING);
    if (ret < 0) {
        LOG_ERR("Failed to configure interrupt: %d", ret);
        return ret;
    }

    // Configure Transmitter
    // Configure Tx GPIO pin
	if (!gpio_is_ready_dt(&ir_tx_pin)) {
        LOG_ERR("Failed to initialise IR transmitter!");
        return 1;
	}
    ret = ret + gpio_pin_configure_dt(&ir_tx_pin, GPIO_OUTPUT_ACTIVE | GPIO_OPEN_DRAIN | GPIO_OUTPUT_LOW);
    if (ret > 0) {
        LOG_ERR("Failed to initialise IR transmitter!");
        return 1;
    }

    // Wait for the IR rx signal to stabilize
    k_msleep(TS1838_SIGNAL_STABILIZATION_TIME_MS);

    LOG_DBG("IR RX & TX initialised!");

    return 0;
}

#define NEC_HEADER_HIGH_US 9000 - 87 
#define NEC_HEADER_LOW_US 4500 - 87
#define NEC_BIT_HIGH_US 560 - 87
#define NEC_BIT_ONE_LOW_US 1990 - 87
#define NEC_BIT_ZERO_LOW_US 560 - 87

void ir_transmit_pulse(uint32_t highDurationUs, uint32_t lowDurationUs) {
    const struct device *gpio_dev = DEVICE_DT_GET(DT_ALIAS(ir_tx));
    // Check IR Device is ready
	if (!device_is_ready(gpio_dev)) {
		LOG_ERR("IR device not found!");
		return;
	}

    gpio_pin_configure(gpio_dev, 26, GPIO_OUTPUT_ACTIVE);

    gpio_pin_set(gpio_dev, 26, 1);
    k_sleep(K_USEC(highDurationUs));
    gpio_pin_set(gpio_dev, 26, 0);
    k_sleep(K_USEC(lowDurationUs));
}

int transmit_ir_packet(IRData irData) {
    // Transmit an NEC Packet
    switch (irData.protocol) {
        case IR_PROTO_NEC:
            /**
             * The NEC protocol consists of the following
             * 1. 9ms leading high
             * 2. 4.5ms low
             * 3. 8-bit address
             * 4. 8-bit logical inverse address
             * 5. 8-bit command
             * 6. 8-bit logical inverse commands
             * 7. Final 562.5us pulse
             * 
             * Logical 0 = 562.5us pulse followed by 562.5us space
             * Logical 1 = 562.5us pulse burst followed by a 1.6875ms pulse space
            */
            // Transmit the header
            LOG_INF("NEC PROTOCOL IDENTIFIED");
            ir_transmit_pulse(NEC_HEADER_HIGH_US, NEC_HEADER_LOW_US);

            // Transmit Data
            for (int i = 31; i >= 0; i--) {
                uint32_t bit = (irData.data >> i) & 0x01;
                printk("%x\n", bit);
                if (bit) {
                    // Transmit a logical 1
                    ir_transmit_pulse(NEC_BIT_HIGH_US, NEC_BIT_ONE_LOW_US);
                } else {
                    // Transmit a logical 0
                    ir_transmit_pulse(NEC_BIT_HIGH_US, NEC_BIT_ZERO_LOW_US);
                }
            }

            // const struct device *gpio_dev = DEVICE_DT_GET(DT_ALIAS(ir_tx));
            // Check IR Device is ready
            // if (!device_is_ready(gpio_dev)) {
            // 	LOG_ERR("IR device not found!");
            // 	return;
            // }
            // // gpio_pin_configure(gpio_dev, 26, GPIO_OUTPUT_ACTIVE);
            // gpio_pin_set(gpio_dev, 26, 1);
            // k_sleep(K_USEC(1000000));
            // gpio_pin_set(gpio_dev, 26, 0);
            // // Start the transmission timer
            // bool timerActive = true;
            // k_timer_start(&ir_tx_timeout_timer, K_NSEC(500), K_NSEC(500)); // Timer should fire every 500ns
            // while (timerActive) {
            //     // Implement each of the phases
            //     if (txTimerUs < 9000) {
            //         // Hold Output Pin High
            //         gpio_pin_set_dt(&ir_tx_pin, 1);
            //     } else if (txTimerUs >= 9000 && txTimerUs < 13500) {
            //         gpio_pin_set_dt(&ir_tx_pin, 0);
            //     } else {
            //         timerActive = false;
            //     }
            // } 
            // k_timer_stop(&ir_tx_timeout_timer);
            // gpio_pin_set_dt(&ir_tx_pin, 0);
            break;
        default:
            LOG_ERR("IR Protocol Not Identified!");
            break;
    }

    LOG_DBG("Message Transmitted!");
    return 0;
}

int ir_transmission_handler() {
	// Init Delay
	k_sleep(K_MSEC(200));

    // Check IR Device is ready
	if (!device_is_ready(ir_dev)) {
		LOG_ERR("IR device not found!");
		return 0;
	}

    // Transmit Incoming Messages
    IRData message;
    while (k_msgq_get(&ir_transmit_q, &message, K_FOREVER) == 0) {
        // Transmit the message
        uint8_t ret;
        IRData irdata = {IR_PROTO_NEC, 0xf7a05f};
        ret = transmit_ir_packet(irdata);
    }
    return 0;
}
```

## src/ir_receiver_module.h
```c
 /** 
 **************************************************************
 * @file src/ir_receiver_module.h
 * @author Alexander Burovanov - 46990480
 * @date 04/05/2024
 * @brief IR Receiver Driver
 * REFERENCE: none
 ***************************************************************
 */
#ifndef AB_IR_REC_MODULE_H_
#define AB_IR_REC_MODULE_H_
#include <stdint.h>
#include <zephyr/device.h>
#include <zephyr/drivers/gpio.h>
#include <zephyr/kernel.h>

// IR Receiver Setup
#define IR_REC_NODE DT_ALIAS(ir_rec)
static const struct device *const ir_rec_dev = DEVICE_DT_GET(IR_REC_NODE);

extern int init_ir_receiver();

#endif
```

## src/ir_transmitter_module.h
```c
 /** 
 **************************************************************
 * @file src/ir_transmitter_module.h
 * @author Alexander Burovanov - 46990480
 * @date 07/05/2024
 * @brief IR Transmitter Driver
 * REFERENCE: none
 ***************************************************************
 */
#ifndef AB_IR_TRANS_MODULE_H_
#define AB_IR_TRANS_MODULE_H_
#include <stdint.h>
#include <zephyr/device.h>
#include <zephyr/drivers/gpio.h>
#include <zephyr/kernel.h>

// IR Transmitter Setup
#define IR_TRANS_NODE DT_ALIAS(ir_trans)
static const struct device *const ir_trans_dev = DEVICE_DT_GET(IR_TRANS_NODE);

extern int init_ir_transmitter();

#endif
```
